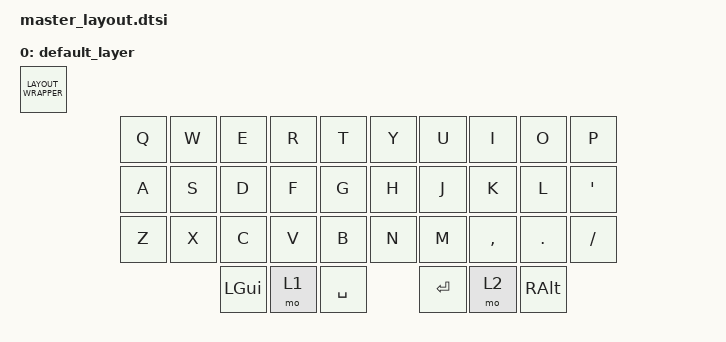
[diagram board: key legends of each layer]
// This file is purely logical. No hardware-specific code here.
/ {
    keymap {
        compatible = "zmk,keymap";
        default_layer {
            bindings = <LAYOUT_WRAPPER(
                &kp Q, &kp W, &kp E, &kp R, &kp T,    &kp Y, &kp U, &kp I, &kp O, &kp P,
                &kp A, &kp S, &kp D, &kp F, &kp G,    &kp H, &kp J, &kp K, &kp L, &kp QUOT,
                &kp Z, &kp X, &kp C, &kp V, &kp B,    &kp N, &kp M, &kp COMMA, &kp DOT, &kp SLASH,
                              &kp LGUI, &mo 1, &kp SPC,  &kp RET, &mo 2, &kp RALT
            )>;
        };
        // Add other layers here using the same LAYOUT_WRAPPER(...) format
    };
};
